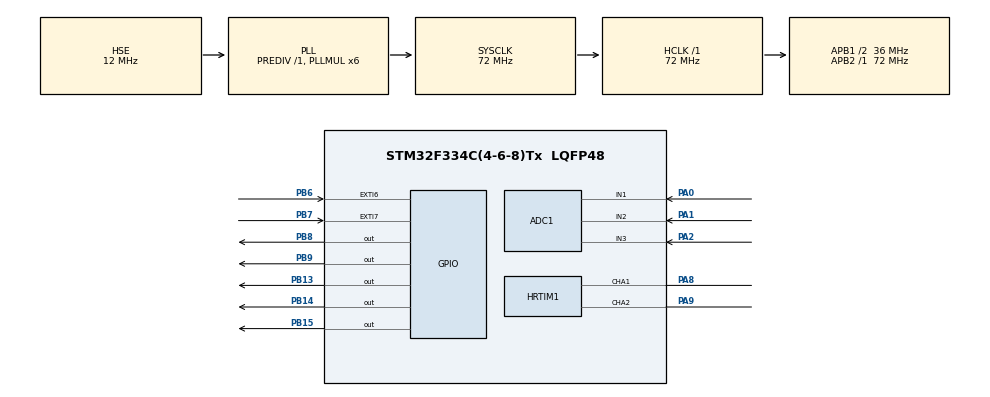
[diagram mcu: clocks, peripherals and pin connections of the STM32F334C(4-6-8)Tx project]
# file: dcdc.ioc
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ADC1.Channel-1\#ChannelRegularConversion=ADC_CHANNEL_1
ADC1.Channel-2\#ChannelRegularConversion=ADC_CHANNEL_2
ADC1.Channel-3\#ChannelRegularConversion=ADC_CHANNEL_3
ADC1.DMAContinuousRequests=ENABLE
ADC1.ExternalTrigConv=ADC_EXTERNALTRIGCONVHRTIM_TRG1
ADC1.NbrOfConversion=3
ADC1.NbrOfConversionFlag=1
ADC1.Offset-1\#ChannelRegularConversion=0
ADC1.Offset-2\#ChannelRegularConversion=0
ADC1.Offset-3\#ChannelRegularConversion=0
ADC1.OffsetNumber-1\#ChannelRegularConversion=ADC_OFFSET_NONE
ADC1.OffsetNumber-2\#ChannelRegularConversion=ADC_OFFSET_NONE
ADC1.OffsetNumber-3\#ChannelRegularConversion=ADC_OFFSET_NONE
ADC1.Rank-1\#ChannelRegularConversion=1
ADC1.Rank-2\#ChannelRegularConversion=2
ADC1.Rank-3\#ChannelRegularConversion=3
ADC1.SamplingTime-1\#ChannelRegularConversion=ADC_SAMPLETIME_7CYCLES_5
ADC1.SamplingTime-2\#ChannelRegularConversion=ADC_SAMPLETIME_7CYCLES_5
ADC1.SamplingTime-3\#ChannelRegularConversion=ADC_SAMPLETIME_7CYCLES_5
ADC1.SubFamily=STM32F334x8
ADC1.master=1
ADC2.Channel-0\#ChannelRegularConversion=ADC_CHANNEL_VREFINT
ADC2.ContinuousConvMode=ENABLE
ADC2.NbrOfConversionFlag=1
ADC2.Offset-0\#ChannelRegularConversion=0
ADC2.OffsetNumber-0\#ChannelRegularConversion=ADC_OFFSET_NONE
ADC2.Rank-0\#ChannelRegularConversion=1
ADC2.SamplingTime-0\#ChannelRegularConversion=ADC_SAMPLETIME_19CYCLES_5
ADC2.SamplingTimeOPAMP-0\#ChannelRegularConversion=ADC_SAMPLETIME_61CYCLES_5
ADC2.SubFamily=STM32F334x8
Dma.ADC1.0.Direction=DMA_PERIPH_TO_MEMORY
Dma.ADC1.0.Instance=DMA1_Channel1
Dma.ADC1.0.MemDataAlignment=DMA_MDATAALIGN_HALFWORD
Dma.ADC1.0.MemInc=DMA_MINC_ENABLE
Dma.ADC1.0.Mode=DMA_CIRCULAR
Dma.ADC1.0.PeriphDataAlignment=DMA_PDATAALIGN_HALFWORD
Dma.ADC1.0.PeriphInc=DMA_PINC_DISABLE
Dma.ADC1.0.Priority=DMA_PRIORITY_VERY_HIGH
Dma.Request0=ADC1
HRTIM1.ADCTrigger1_Source1=HRTIM_ADCTRIGGEREVENT13_TIMERA_CMP2
HRTIM1.ADCTrigger_Id1=HRTIM_ADCTRIGGER_1
HRTIM1.CompareUnit1-Output_TA1TA2=HRTIM_COMPAREUNIT_1
HRTIM1.CompareUnit2-Output_TA1TA2=HRTIM_COMPAREUNIT_2
HRTIM1.CompareUnit3-MasterTimer=HRTIM_COMPAREUNIT_3
HRTIM1.CompareUnit3-Output_TA1TA2=HRTIM_COMPAREUNIT_3
HRTIM1.CompareValue1-Output_TA1TA2=0xFFDF
HRTIM1.CompareValue2-Output_TA1TA2=22680
HRTIM1.CompareValue3-MasterTimer=23040
HRTIM1.DeadTimeInsertion-Output_TA1TA2=HRTIM_TIMDEADTIMEINSERTION_ENABLED
HRTIM1.FallingValue-Output_TA1TA2=300
HRTIM1.InterruptRequests1_Master=HRTIM_MASTER_IT_MREP
HRTIM1.NumberADCTriggerSource1=1
HRTIM1.NumberInterruptRequests_Master-MasterTimer=1
HRTIM1.NumberResetSource1-Output_TA1TA2=1
HRTIM1.NumberResetTrigger-Output_TA1TA2=1
HRTIM1.NumberSetSource1-Output_TA1TA2=1
HRTIM1.NumberUpdateTrigger-Output_TA1TA2=1
HRTIM1.Periode_MASTER=46080
HRTIM1.Periode_TA=46080
HRTIM1.PreloadEnable-MasterTimer=HRTIM_PRELOAD_ENABLED
HRTIM1.PreloadEnable-Output_TA1TA2=HRTIM_PRELOAD_ENABLED
HRTIM1.RepetitionCounter-MasterTimer=3
HRTIM1.RepetitionUpdate-MasterTimer=HRTIM_UPDATEONREPETITION_ENABLED
HRTIM1.RepetitionUpdate-Output_TA1TA2=HRTIM_UPDATEONREPETITION_ENABLED
HRTIM1.ResetOutput1_Source1-Output_TA1TA2=HRTIM_OUTPUTRESET_TIMCMP3
HRTIM1.ResetTrigger1-Output_TA1TA2=HRTIM_TIMRESETTRIGGER_MASTER_CMP3
HRTIM1.RisingValue-Output_TA1TA2=300
HRTIM1.SetOutput1_Source1-Output_TA1TA2=HRTIM_OUTPUTSET_TIMCMP1
HRTIM1.UpdateTrigger1-Output_TA1TA2=HRTIM_TIMUPDATETRIGGER_TIMER_A
Mcu.Family=STM32F3
Mcu.Name=STM32F334C(4-6-8)Tx
Mcu.Package=LQFP48
NVIC.DMA1_Channel1_IRQn=true\:0\:0\:false\:false\:true\:false\:true\:true
NVIC.EXTI9_5_IRQn=true\:0\:0\:false\:false\:true\:true\:true\:true
NVIC.HRTIM1_Master_IRQn=true\:5\:0\:true\:false\:true\:true\:true\:true
NVIC.PriorityGroup=NVIC_PRIORITYGROUP_4
NVIC.TIM2_IRQn=true\:6\:0\:true\:false\:true\:true\:true\:true
PA0.Mode=IN1-Single-Ended
PA0.Signal=ADC1_IN1
PA1.Mode=IN2-Single-Ended
PA1.Signal=ADC1_IN2
PA13.Mode=Serial_Wire
PA13.Signal=SYS_JTMS-SWDIO
PA14.Mode=Serial_Wire
PA14.Signal=SYS_JTCK-SWCLK
PA2.Mode=IN3-Single-Ended
PA2.Signal=ADC1_IN3
PA8.Mode=Output_TA1TA2
PA8.Signal=HRTIM1_CHA1
PA9.Mode=Output_TA1TA2
PA9.Signal=HRTIM1_CHA2
PB13.PinState=GPIO_PIN_SET
PB13.Signal=GPIO_Output
PB14.PinState=GPIO_PIN_SET
PB14.Signal=GPIO_Output
PB15.PinState=GPIO_PIN_SET
PB15.Signal=GPIO_Output
PB6.GPIO_ModeDefaultEXTI=GPIO_MODE_IT_FALLING
PB6.GPIO_PuPd=GPIO_PULLUP
PB6.Signal=GPXTI6
PB7.GPIO_ModeDefaultEXTI=GPIO_MODE_IT_FALLING
PB7.GPIO_PuPd=GPIO_PULLUP
PB7.Signal=GPXTI7
PB8.GPIO_ModeDefaultOutputPP=GPIO_MODE_OUTPUT_OD
PB8.GPIO_PuPd=GPIO_PULLUP
PB8.GPIO_Speed=GPIO_SPEED_FREQ_HIGH
PB8.PinState=GPIO_PIN_SET
PB8.Signal=GPIO_Output
PB9.GPIO_ModeDefaultOutputPP=GPIO_MODE_OUTPUT_OD
PB9.GPIO_PuPd=GPIO_PULLUP
PB9.GPIO_Speed=GPIO_SPEED_FREQ_HIGH
PB9.PinState=GPIO_PIN_SET
PB9.Signal=GPIO_Output
PF0\ /\ OSC_IN.Mode=HSE-External-Oscillator
PF0\ /\ OSC_IN.Signal=RCC_OSC_IN
PF1\ /\ OSC_OUT.Mode=HSE-External-Oscillator
PF1\ /\ OSC_OUT.Signal=RCC_OSC_OUT
ProjectManager.HeapSize=0x200
ProjectManager.StackSize=0x400
ProjectManager.TargetToolchain=CMake
RCC.AHBFreq_Value=72000000
RCC.APB1CLKDivider=RCC_HCLK_DIV2
RCC.APB1Freq_Value=36000000
RCC.APB1TimFreq_Value=72000000
RCC.APB2Freq_Value=72000000
RCC.APB2TimFreq_Value=72000000
RCC.CortexFreq_Value=72000000
RCC.HCLKFreq_Value=72000000
RCC.HRTIMSelection=RCC_HRTIM1CLK_PLLCLK
RCC.HSE_VALUE=12000000
RCC.HSI_VALUE=8000000
RCC.LSE_VALUE=32768
RCC.PLLMUL=RCC_PLL_MUL6
RCC.PLLSourceVirtual=RCC_PLLSOURCE_HSE
RCC.SYSCLKFreq_VALUE=72000000
RCC.SYSCLKSourceVirtual=RCC_SYSCLKSOURCE_PLLCLK
TIM2.Period=9
TIM2.Prescaler=7199
VP_ADC2_Vref_Input.Mode=IN-Vrefint
VP_HRTIM1_VS_hrtimMasterTimerNoOutput.Mode=MasterTimer
VP_TIM2_VS_ClockSourceINT.Mode=Internal
board=custom

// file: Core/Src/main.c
/* USER CODE BEGIN Header */
/**
  ******************************************************************************
  * @file           : main.c
  * @brief          : Main program body
  ******************************************************************************
  * @attention
  *
  * Copyright (c) 2025 STMicroelectronics.
  * All rights reserved.
  *
  * This software is licensed under terms that can be found in the LICENSE file
  * in the root directory of this software component.
  * If no LICENSE file comes with this software, it is provided AS-IS.
  *
  ******************************************************************************
  */
/* USER CODE END Header */
#include "main.h"
#include "adc.h"
#include "dma.h"
#include "hrtim.h"
#include "tim.h"
#include "gpio.h"

void SystemClock_Config(void);
/* USER CODE BEGIN PFP */
extern void UserInit();
extern void UserLoop();
/* USER CODE END PFP */

int main(void)
{

  /* MCU Configuration--------------------------------------------------------*/

  /* Reset of all peripherals, Initializes the Flash interface and the Systick. */
  HAL_Init();

  /* Configure the system clock */
  SystemClock_Config();

  /* Initialize all configured peripherals */
  MX_GPIO_Init();
  MX_DMA_Init();
  MX_ADC1_Init();
  MX_HRTIM1_Init();
  MX_ADC2_Init();
  MX_TIM2_Init();
  /* USER CODE BEGIN 2 */
  UserInit();
  /* USER CODE END 2 */

  /* Infinite loop */
  while (1)
  {

    /* USER CODE BEGIN 3 */
    UserLoop();
  }
  /* USER CODE END 3 */
}

void SystemClock_Config(void)
{
  RCC_OscInitTypeDef RCC_OscInitStruct = {0};
  RCC_ClkInitTypeDef RCC_ClkInitStruct = {0};
  RCC_PeriphCLKInitTypeDef PeriphClkInit = {0};

  /** Initializes the RCC Oscillators according to the specified parameters
  * in the RCC_OscInitTypeDef structure.
  */
  RCC_OscInitStruct.OscillatorType = RCC_OSCILLATORTYPE_HSE;
  RCC_OscInitStruct.HSEState = RCC_HSE_ON;
  RCC_OscInitStruct.HSEPredivValue = RCC_HSE_PREDIV_DIV1;
  RCC_OscInitStruct.HSIState = RCC_HSI_ON;
  RCC_OscInitStruct.PLL.PLLState = RCC_PLL_ON;
  RCC_OscInitStruct.PLL.PLLSource = RCC_PLLSOURCE_HSE;
  RCC_OscInitStruct.PLL.PLLMUL = RCC_PLL_MUL6;
  if (HAL_RCC_OscConfig(&RCC_OscInitStruct) != HAL_OK)
  {
    Error_Handler();
  }

  /** Initializes the CPU, AHB and APB buses clocks
  */
  RCC_ClkInitStruct.ClockType = RCC_CLOCKTYPE_HCLK|RCC_CLOCKTYPE_SYSCLK
                              |RCC_CLOCKTYPE_PCLK1|RCC_CLOCKTYPE_PCLK2;
  RCC_ClkInitStruct.SYSCLKSource = RCC_SYSCLKSOURCE_PLLCLK;
  RCC_ClkInitStruct.AHBCLKDivider = RCC_SYSCLK_DIV1;
  RCC_ClkInitStruct.APB1CLKDivider = RCC_HCLK_DIV2;
  RCC_ClkInitStruct.APB2CLKDivider = RCC_HCLK_DIV1;

  if (HAL_RCC_ClockConfig(&RCC_ClkInitStruct, FLASH_LATENCY_2) != HAL_OK)
  {
    Error_Handler();
  }
  PeriphClkInit.PeriphClockSelection = RCC_PERIPHCLK_HRTIM1|RCC_PERIPHCLK_ADC12;
  PeriphClkInit.Adc12ClockSelection = RCC_ADC12PLLCLK_DIV1;
  PeriphClkInit.Hrtim1ClockSelection = RCC_HRTIM1CLK_PLLCLK;
  if (HAL_RCCEx_PeriphCLKConfig(&PeriphClkInit) != HAL_OK)
  {
    Error_Handler();
  }
}

void Error_Handler(void)
{
  __disable_irq();
  while (1)
  {
  }
}
